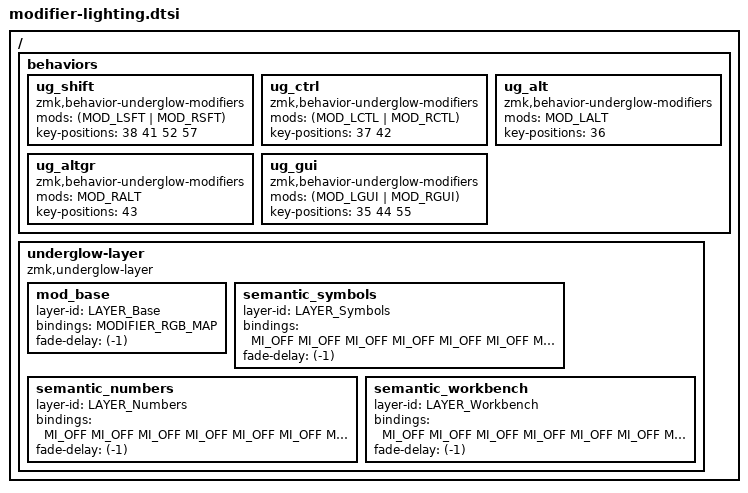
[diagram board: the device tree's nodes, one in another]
#include <behaviors/ug_modifiers.dtsi>
#include <dt-bindings/zmk/modifiers.h>

/ {
    behaviors {
        ug_shift: ug_shift {
            compatible = "zmk,behavior-underglow-modifiers";
            #binding-cells = <2>;
            mods = <(MOD_LSFT | MOD_RSFT)>;
            key-positions = <38 41 52 57>;
        };
        ug_ctrl: ug_ctrl {
            compatible = "zmk,behavior-underglow-modifiers";
            #binding-cells = <2>;
            mods = <(MOD_LCTL | MOD_RCTL)>;
            key-positions = <37 42>;
        };
        ug_alt: ug_alt {
            compatible = "zmk,behavior-underglow-modifiers";
            #binding-cells = <2>;
            mods = <MOD_LALT>;
            key-positions = <36>;
        };
        ug_altgr: ug_altgr {
            compatible = "zmk,behavior-underglow-modifiers";
            #binding-cells = <2>;
            mods = <MOD_RALT>;
            key-positions = <43>;
        };
        ug_gui: ug_gui {
            compatible = "zmk,behavior-underglow-modifiers";
            #binding-cells = <2>;
            mods = <(MOD_LGUI | MOD_RGUI)>;
            key-positions = <35 44 55>;
        };
    };
};

#define MI_OFF &ug 0x000000
#define MI_SHIFT &ug_shift 0x000000 0x00FFFF
#define MI_CTRL &ug_ctrl 0x000000 0x00FF00
#define MI_ALT &ug_alt 0x000000 0xFF8000
#define MI_ALTGR &ug_altgr 0x000000 0xFF00FF
#define MI_GUI &ug_gui 0x000000 0xFFFF00

#define SI_CYAN &ug 0x00FFFF
#define SI_ORANGE &ug 0xFF8000
#define SI_YELLOW &ug 0xFFFF00
#define SI_VIOLET &ug 0x8000FF
#define SI_GREEN &ug 0x00FF00
#define SI_MAGENTA &ug 0xFF00FF
#define SI_CONTROL &ug 0x404040

#define MODIFIER_RGB_MAP \
    MI_OFF MI_OFF MI_OFF MI_OFF MI_OFF                                       MI_OFF MI_OFF MI_OFF MI_OFF MI_OFF \
    MI_OFF MI_OFF MI_OFF MI_OFF MI_OFF MI_OFF                         MI_OFF MI_OFF MI_OFF MI_OFF MI_OFF MI_OFF \
    MI_OFF MI_OFF MI_OFF MI_OFF MI_OFF MI_OFF                         MI_OFF MI_OFF MI_OFF MI_OFF MI_OFF MI_OFF \
    MI_OFF MI_GUI MI_ALT MI_CTRL MI_SHIFT MI_OFF                      MI_OFF MI_SHIFT MI_CTRL MI_ALTGR MI_GUI MI_OFF \
    MI_OFF MI_OFF MI_OFF MI_OFF MI_OFF MI_OFF MI_SHIFT MI_CTRL MI_OFF MI_GUI MI_CTRL MI_SHIFT MI_OFF MI_OFF MI_OFF MI_OFF MI_OFF MI_OFF \
    MI_OFF MI_OFF MI_OFF MI_OFF MI_OFF        MI_OFF MI_OFF MI_ALT    MI_ALTGR MI_OFF MI_OFF        MI_OFF MI_OFF MI_OFF MI_OFF MI_OFF

/ {
    underglow-layer {
        compatible = "zmk,underglow-layer";
        mod_base {
            layer-id = <LAYER_Base>;
            bindings = <MODIFIER_RGB_MAP>;
            fade-delay = <(-1)>;
        };
        semantic_symbols {
            layer-id = <LAYER_Symbols>;
            bindings = <
                MI_OFF MI_OFF MI_OFF MI_OFF MI_OFF                                      MI_OFF MI_OFF MI_OFF MI_OFF MI_OFF
                MI_OFF MI_OFF MI_OFF MI_OFF MI_OFF MI_OFF                        MI_OFF MI_OFF MI_OFF MI_OFF MI_OFF MI_OFF
                SI_MAGENTA SI_ORANGE SI_CYAN SI_GREEN SI_GREEN SI_ORANGE         SI_ORANGE SI_MAGENTA MI_OFF MI_OFF MI_OFF MI_OFF
                SI_MAGENTA SI_CYAN SI_CYAN SI_GREEN SI_GREEN SI_ORANGE            SI_CYAN SI_CYAN SI_ORANGE SI_ORANGE SI_MAGENTA SI_ORANGE
                MI_OFF SI_ORANGE SI_MAGENTA SI_GREEN SI_GREEN SI_ORANGE MI_OFF MI_OFF SI_CONTROL MI_OFF MI_OFF MI_OFF SI_CYAN SI_CYAN SI_CYAN SI_CYAN SI_MAGENTA MI_OFF
                MI_OFF MI_OFF MI_OFF SI_GREEN SI_GREEN        MI_OFF MI_OFF MI_OFF MI_OFF MI_OFF MI_OFF        MI_OFF MI_OFF SI_ORANGE MI_OFF MI_OFF
            >;
            fade-delay = <(-1)>;
        };
        semantic_numbers {
            layer-id = <LAYER_Numbers>;
            bindings = <
                MI_OFF MI_OFF MI_OFF MI_OFF MI_OFF                                      MI_OFF MI_OFF MI_OFF MI_OFF MI_OFF
                MI_OFF MI_OFF MI_OFF MI_OFF MI_OFF MI_OFF                        MI_OFF MI_OFF MI_OFF MI_OFF MI_OFF MI_OFF
                MI_OFF SI_VIOLET SI_VIOLET SI_VIOLET SI_VIOLET SI_VIOLET           MI_OFF SI_CYAN SI_CYAN SI_CYAN SI_ORANGE MI_OFF
                MI_OFF SI_VIOLET SI_VIOLET SI_VIOLET SI_VIOLET SI_VIOLET           SI_CYAN SI_CYAN SI_CYAN SI_CYAN SI_ORANGE MI_OFF
                MI_OFF SI_VIOLET SI_VIOLET MI_OFF MI_OFF MI_OFF MI_OFF MI_OFF MI_OFF MI_OFF MI_OFF MI_OFF SI_YELLOW SI_CYAN SI_CYAN SI_CYAN SI_ORANGE MI_OFF
                MI_OFF MI_OFF MI_OFF MI_OFF MI_OFF        MI_OFF MI_OFF MI_OFF MI_OFF MI_OFF MI_OFF        MI_OFF MI_OFF MI_OFF MI_OFF MI_OFF
            >;
            fade-delay = <(-1)>;
        };
        semantic_workbench {
            layer-id = <LAYER_Workbench>;
            bindings = <
                MI_OFF MI_OFF MI_OFF MI_OFF MI_OFF                                      MI_OFF MI_OFF MI_OFF MI_OFF MI_OFF
                MI_OFF MI_OFF MI_OFF MI_OFF MI_OFF MI_OFF                        MI_OFF MI_OFF MI_OFF MI_OFF MI_OFF MI_OFF
                MI_OFF SI_YELLOW SI_YELLOW SI_YELLOW SI_YELLOW SI_YELLOW           SI_CYAN SI_CYAN SI_CYAN SI_CYAN SI_CYAN MI_OFF
                MI_OFF SI_YELLOW SI_GREEN SI_GREEN MI_OFF MI_OFF                  SI_CYAN SI_CYAN SI_CYAN SI_CYAN SI_CYAN MI_OFF
                MI_OFF SI_VIOLET SI_VIOLET SI_VIOLET SI_VIOLET MI_OFF MI_OFF MI_OFF MI_OFF MI_OFF MI_OFF MI_OFF MI_OFF MI_OFF MI_OFF MI_OFF MI_OFF MI_OFF
                MI_OFF MI_OFF MI_OFF MI_OFF MI_OFF        MI_OFF MI_OFF MI_OFF MI_OFF MI_OFF MI_OFF        MI_OFF MI_OFF MI_OFF MI_OFF MI_OFF
            >;
            fade-delay = <(-1)>;
        };
    };
};

#undef MODIFIER_RGB_MAP
#undef MI_OFF
#undef MI_SHIFT
#undef MI_CTRL
#undef MI_ALT
#undef MI_ALTGR
#undef MI_GUI
#undef SI_CYAN
#undef SI_ORANGE
#undef SI_YELLOW
#undef SI_VIOLET
#undef SI_GREEN
#undef SI_MAGENTA
#undef SI_CONTROL
